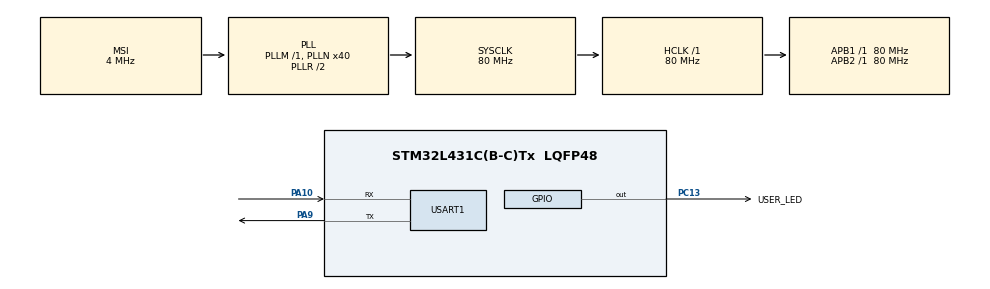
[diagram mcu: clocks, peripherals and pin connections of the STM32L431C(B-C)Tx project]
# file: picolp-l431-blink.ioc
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Mcu.Family=STM32L4
Mcu.Name=STM32L431C(B-C)Tx
Mcu.Package=LQFP48
NVIC.PriorityGroup=NVIC_PRIORITYGROUP_4
NVIC.USART1_IRQn=true\:0\:0\:false\:false\:true\:true\:true\:true
PA10.Mode=Asynchronous
PA10.Signal=USART1_RX
PA13\ (JTMS-SWDIO).Mode=Serial_Wire
PA13\ (JTMS-SWDIO).Signal=SYS_JTMS-SWDIO
PA14\ (JTCK-SWCLK).Mode=Serial_Wire
PA14\ (JTCK-SWCLK).Signal=SYS_JTCK-SWCLK
PA9.Mode=Asynchronous
PA9.Signal=USART1_TX
PC13.GPIO_Label=USER_LED
PC13.Signal=GPIO_Output
PH0-OSC_IN\ (PH0).Mode=HSE-External-Oscillator
PH0-OSC_IN\ (PH0).Signal=RCC_OSC_IN
PH1-OSC_OUT\ (PH1).Mode=HSE-External-Oscillator
PH1-OSC_OUT\ (PH1).Signal=RCC_OSC_OUT
ProjectManager.HeapSize=0x200
ProjectManager.StackSize=0x400
ProjectManager.TargetToolchain=CMake
RCC.ADCFreq_Value=16000000
RCC.AHBFreq_Value=80000000
RCC.APB1Freq_Value=80000000
RCC.APB1TimFreq_Value=80000000
RCC.APB2Freq_Value=80000000
RCC.APB2TimFreq_Value=80000000
RCC.CortexFreq_Value=80000000
RCC.HCLKFreq_Value=80000000
RCC.HSE_VALUE=16000000
RCC.HSI48_VALUE=48000000
RCC.HSI_VALUE=16000000
RCC.LSE_VALUE=32768
RCC.MSI_VALUE=4000000
RCC.PLLN=40
RCC.SYSCLKFreq_VALUE=80000000
RCC.SYSCLKSource=RCC_SYSCLKSOURCE_PLLCLK
RCC.VCOOutputFreq_Value=160000000
USART1.VirtualMode-Asynchronous=VM_ASYNC
board=custom

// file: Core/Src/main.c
/* USER CODE BEGIN Header */
/**
  ******************************************************************************
  * @file           : main.c
  * @brief          : Main program body
  ******************************************************************************
  * @attention
  *
  * Copyright (c) 2025 STMicroelectronics.
  * All rights reserved.
  *
  * This software is licensed under terms that can be found in the LICENSE file
  * in the root directory of this software component.
  * If no LICENSE file comes with this software, it is provided AS-IS.
  *
  ******************************************************************************
  */
/* USER CODE END Header */
#include "main.h"
#include "usart.h"
#include "gpio.h"

/* USER CODE BEGIN PD */

#define SERIAL_BUFSIZE 16
#define SERIAL_UART huart1

/* USER CODE END PD */

/* USER CODE BEGIN PV */

// Serial ring buffer
struct {
  char buf[SERIAL_BUFSIZE];
  char *head;
  char *tail;
  size_t len;
} serial_buf;

// RX byte buffer
char rx_buf;

/* USER CODE END PV */

void SystemClock_Config(void);

int main(void)
{

  /* MCU Configuration--------------------------------------------------------*/

  /* Reset of all peripherals, Initializes the Flash interface and the Systick. */
  HAL_Init();

  /* Configure the system clock */
  SystemClock_Config();

  /* Initialize all configured peripherals */
  MX_GPIO_Init();
  MX_USART1_UART_Init();
  /* USER CODE BEGIN 2 */

  // Clear the buffer and begin receiving
  serial_buf.head = serial_buf.buf;
  serial_buf.tail = serial_buf.buf;
  serial_buf.len = 0;
  HAL_UART_Receive_IT(&SERIAL_UART, (uint8_t *) &rx_buf, sizeof(rx_buf));

  /* USER CODE END 2 */

  /* Infinite loop */
  /* USER CODE BEGIN WHILE */
  while (1)
  {
    // Send the buffer back over the serial port
    // Blink code is in stm32l4xx_it.c
    char next_char;
    uint8_t next_char_valid = 0;
    // Atomic block
    __disable_irq();
    if(serial_buf.len > 0) {
      next_char = *serial_buf.tail;
      serial_buf.len--;
      if(++serial_buf.tail >= serial_buf.buf+SERIAL_BUFSIZE) {
        serial_buf.tail = serial_buf.buf;
      }
      next_char_valid = 1;
    }
    __enable_irq();
    // Send char if valid
    if(next_char_valid) {
      HAL_UART_Transmit(&SERIAL_UART, (uint8_t *) &next_char, 1, HAL_MAX_DELAY);
    }

    /* USER CODE END WHILE */

  }
}

void SystemClock_Config(void)
{
  RCC_OscInitTypeDef RCC_OscInitStruct = {0};
  RCC_ClkInitTypeDef RCC_ClkInitStruct = {0};

  /** Configure the main internal regulator output voltage
  */
  if (HAL_PWREx_ControlVoltageScaling(PWR_REGULATOR_VOLTAGE_SCALE1) != HAL_OK)
  {
    Error_Handler();
  }

  /** Initializes the RCC Oscillators according to the specified parameters
  * in the RCC_OscInitTypeDef structure.
  */
  RCC_OscInitStruct.OscillatorType = RCC_OSCILLATORTYPE_MSI;
  RCC_OscInitStruct.MSIState = RCC_MSI_ON;
  RCC_OscInitStruct.MSICalibrationValue = 0;
  RCC_OscInitStruct.MSIClockRange = RCC_MSIRANGE_6;
  RCC_OscInitStruct.PLL.PLLState = RCC_PLL_ON;
  RCC_OscInitStruct.PLL.PLLSource = RCC_PLLSOURCE_MSI;
  RCC_OscInitStruct.PLL.PLLM = 1;
  RCC_OscInitStruct.PLL.PLLN = 40;
  RCC_OscInitStruct.PLL.PLLP = RCC_PLLP_DIV7;
  RCC_OscInitStruct.PLL.PLLQ = RCC_PLLQ_DIV2;
  RCC_OscInitStruct.PLL.PLLR = RCC_PLLR_DIV2;
  if (HAL_RCC_OscConfig(&RCC_OscInitStruct) != HAL_OK)
  {
    Error_Handler();
  }

  /** Initializes the CPU, AHB and APB buses clocks
  */
  RCC_ClkInitStruct.ClockType = RCC_CLOCKTYPE_HCLK|RCC_CLOCKTYPE_SYSCLK
                              |RCC_CLOCKTYPE_PCLK1|RCC_CLOCKTYPE_PCLK2;
  RCC_ClkInitStruct.SYSCLKSource = RCC_SYSCLKSOURCE_PLLCLK;
  RCC_ClkInitStruct.AHBCLKDivider = RCC_SYSCLK_DIV1;
  RCC_ClkInitStruct.APB1CLKDivider = RCC_HCLK_DIV1;
  RCC_ClkInitStruct.APB2CLKDivider = RCC_HCLK_DIV1;

  if (HAL_RCC_ClockConfig(&RCC_ClkInitStruct, FLASH_LATENCY_4) != HAL_OK)
  {
    Error_Handler();
  }
}

/* USER CODE BEGIN 4 */

void HAL_UART_RxCpltCallback(UART_HandleTypeDef *huartx) {
  if(huartx->Instance == SERIAL_UART.Instance) {
    // Receive finished
    if(serial_buf.len < SERIAL_BUFSIZE) {
      // Append to buffer
      *serial_buf.head = rx_buf;
      serial_buf.len++;
      if(++serial_buf.head >= serial_buf.buf+SERIAL_BUFSIZE) {
        // Wrap buffer pointer
        serial_buf.head = serial_buf.buf;
      }
    }
    // Restart listening
    HAL_UART_Receive_IT(&SERIAL_UART, (uint8_t *) &rx_buf, sizeof(rx_buf));
  }
}

/* USER CODE END 4 */

void Error_Handler(void)
{
  __disable_irq();
  while (1)
  {
  }
}
